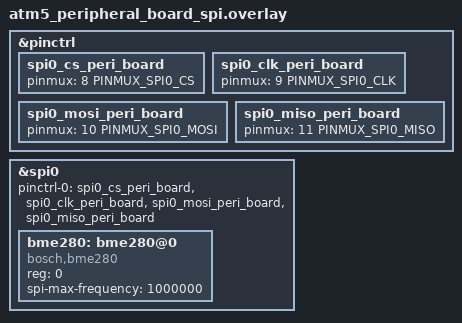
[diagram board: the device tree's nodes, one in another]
/*
 * SPDX-License-Identifier: LicenseRef-Atmosic
 *
 * Copyright (c) 2026 Atmosic
 */
#include <atm5xxx_2_pinmux.h>

&pinctrl {
	// SPI 0
	spi0_cs_peri_board: spi0_cs_peri_board {
		pinmux = <8 PINMUX_SPI0_CS>;
	};

	spi0_clk_peri_board: spi0_clk_peri_board {
		pinmux = <9 PINMUX_SPI0_CLK>;
	};

	spi0_mosi_peri_board: spi0_mosi_peri_board {
		pinmux = <10 PINMUX_SPI0_MOSI>;
	};

	spi0_miso_peri_board: spi0_miso_peri_board {
		pinmux = <11 PINMUX_SPI0_MISO>;
	};
};

&spi0 {
	pinctrl-0 = <&spi0_cs_peri_board  &spi0_clk_peri_board &spi0_mosi_peri_board &spi0_miso_peri_board>;
	status = "okay";

	bme280: bme280@0 {
		compatible = "bosch,bme280";
		reg = <0>;
		spi-max-frequency = <1000000>;
		status = "okay";
	};
};
